AUTOSAR XML (schema 3-2-1)
package /seat-heater/Heater_swc
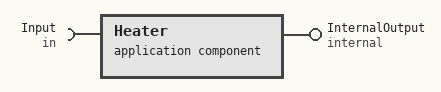
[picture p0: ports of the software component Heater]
  application software component type Heater
    require port Input: provided-interface=in
    provide port InternalOutput: provided-interface=internal
  internal behavior HeaterBehavior: compontent=Heater
  swc implementation HeaterImplementation: behavior=HeaterBehavior
